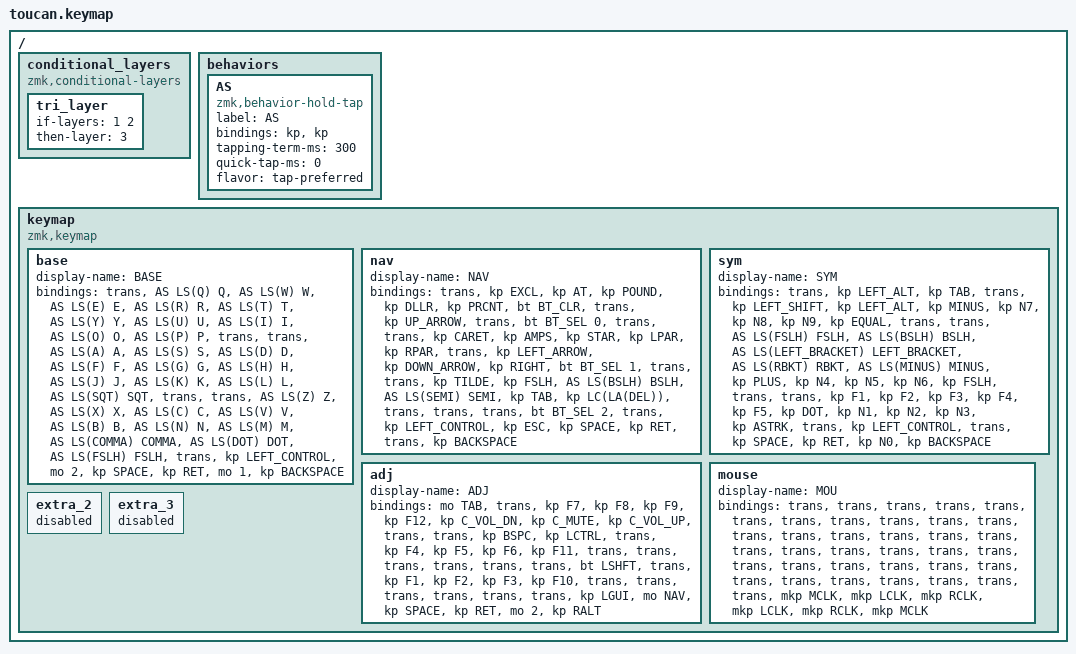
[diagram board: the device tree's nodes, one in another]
#include <behaviors.dtsi>
#include <dt-bindings/zmk/bt.h>
#include <dt-bindings/zmk/keys.h>
#include <dt-bindings/zmk/pointing.h>

#define BASE 0
#define NAV  1
#define SYM  2
#define ADJ  3

/ {
    conditional_layers {
        compatible = "zmk,conditional-layers";

        tri_layer {
            if-layers = <1 2>;
            then-layer = <3>;
        };
    };

    behaviors {
        AS: AS {
            compatible = "zmk,behavior-hold-tap";
            label = "AS";
            bindings = <&kp>, <&kp>;

            #binding-cells = <2>;
            tapping-term-ms = <300>;
            quick-tap-ms = <0>;
            flavor = "tap-preferred";
        };
    };

    keymap {
        compatible = "zmk,keymap";

        base {
            display-name = "BASE";
            bindings = <
&trans  &AS LS(Q) Q  &AS LS(W) W  &AS LS(E) E  &AS LS(R) R  &AS LS(T) T  &AS LS(Y) Y  &AS LS(U) U  &AS LS(I) I  &AS LS(O) O  &AS LS(P) P  &trans  &trans  &AS LS(A) A  &AS LS(S) S  &AS LS(D) D  &AS LS(F) F  &AS LS(G) G  &AS LS(H) H  &AS LS(J) J  &AS LS(K) K  &AS LS(L) L  &AS LS(SQT) SQT  &trans  &trans  &AS LS(Z) Z  &AS LS(X) X  &AS LS(C) C  &AS LS(V) V  &AS LS(B) B  &AS LS(N) N  &AS LS(M) M  &AS LS(COMMA) COMMA  &AS LS(DOT) DOT  &AS LS(FSLH) FSLH  &trans  &kp LEFT_CONTROL  &mo 2  &kp SPACE  &kp RET  &mo 1  &kp BACKSPACE
            >;
        };

        nav {
            display-name = "NAV";
            bindings = <
&trans  &kp EXCL  &kp AT  &kp POUND  &kp DLLR  &kp PRCNT  &bt BT_CLR  &trans  &kp UP_ARROW  &trans  &bt BT_SEL 0  &trans  &trans  &kp CARET  &kp AMPS  &kp STAR  &kp LPAR  &kp RPAR  &trans  &kp LEFT_ARROW  &kp DOWN_ARROW  &kp RIGHT  &bt BT_SEL 1  &trans  &trans  &kp TILDE  &kp FSLH  &AS LS(BSLH) BSLH  &AS LS(SEMI) SEMI  &kp TAB  &kp LC(LA(DEL))  &trans  &trans  &trans  &bt BT_SEL 2  &trans  &kp LEFT_CONTROL  &kp ESC  &kp SPACE  &kp RET  &trans  &kp BACKSPACE
            >;
        };

        sym {
            display-name = "SYM";
            bindings = <
&trans  &kp LEFT_ALT  &kp TAB  &trans  &kp LEFT_SHIFT  &kp LEFT_ALT  &kp MINUS  &kp N7  &kp N8  &kp N9  &kp EQUAL  &trans  &trans  &AS LS(FSLH) FSLH  &AS LS(BSLH) BSLH  &AS LS(LEFT_BRACKET) LEFT_BRACKET  &AS LS(RBKT) RBKT  &AS LS(MINUS) MINUS  &kp PLUS  &kp N4  &kp N5  &kp N6  &kp FSLH  &trans  &trans  &kp F1  &kp F2  &kp F3  &kp F4  &kp F5  &kp DOT  &kp N1  &kp N2  &kp N3  &kp ASTRK  &trans  &kp LEFT_CONTROL  &trans  &kp SPACE  &kp RET  &kp N0  &kp BACKSPACE
            >;
        };

        adj {
            display-name = "ADJ";
            bindings = <
&mo TAB  &trans  &kp F7  &kp F8  &kp F9  &kp F12  &kp C_VOL_DN  &kp C_MUTE  &kp C_VOL_UP  &trans  &trans  &kp BSPC  &kp LCTRL  &trans  &kp F4  &kp F5  &kp F6  &kp F11  &trans  &trans  &trans  &trans  &trans  &trans  &bt LSHFT  &trans  &kp F1  &kp F2  &kp F3  &kp F10  &trans  &trans  &trans  &trans  &trans  &trans  &kp LGUI  &mo NAV  &kp SPACE  &kp RET  &mo 2  &kp RALT
            >;
        };

        mouse {
            display-name = "MOU";
            bindings = <
&trans  &trans  &trans  &trans  &trans  &trans  &trans  &trans  &trans  &trans  &trans  &trans  &trans  &trans  &trans  &trans  &trans  &trans  &trans  &trans  &trans  &trans  &trans  &trans  &trans  &trans  &trans  &trans  &trans  &trans  &trans  &trans  &trans  &trans  &trans  &trans  &mkp MCLK  &mkp LCLK  &mkp RCLK  &mkp LCLK  &mkp RCLK  &mkp MCLK
            >;
        };

        extra_2 { status = "reserved"; };

        extra_3 { status = "reserved"; };
    };
};
